# psoc6_04 register map
Vendor: Cypress Semiconductor; Series: PSoC6_04; File version: 1.0
CPU: CM4 r0p1, little endian, MPU, FPU, VTOR, 3 interrupt priority bits
Registers are 32-bit, read-write, reset 0x0 unless marked. A register's access mark holds for its fields unless they carry their own. Offsets are from the block's base; [hi:lo] are bit positions; lines under a group give offsets from that group; {n}, {i} and the like mark numbered series; <NAME> marks a mode.

## PASS — PASS top-level MMIO (AREF, LPOSC, FIFO, INTR, Trigger)
Base 0x409F0000
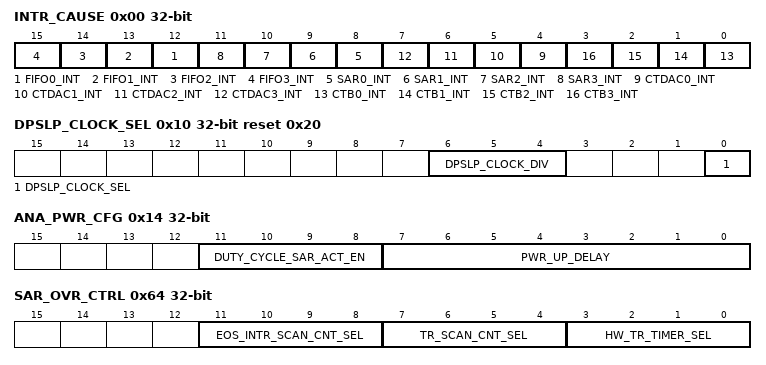
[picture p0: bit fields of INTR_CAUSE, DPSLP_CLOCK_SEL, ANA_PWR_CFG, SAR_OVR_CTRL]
0x00 INTR_CAUSE ro — Interrupt cause register
  [n+12] FIFO{n}_INT (n=0..3) — FIFO{n} interrupt pending
  [n+8] SAR{n}_INT (n=0..3) — SAR{n} interrupt pending
  [n+4] CTDAC{n}_INT (n=0..3) — CTDAC{n} interrupt pending
  [n] CTB{n}_INT (n=0..3) — CTB{n} interrupt pending
0x10 DPSLP_CLOCK_SEL reset 0x20 — Deepsleep clock select
  [6:4] DPSLP_CLOCK_DIV — CLK_DPSLP divider
    0=NO_DIV (Transparent mode, feed through selected clock source w/o dividing.); 1=DIV_BY_2 (Divide selected clock source by 2); 2=DIV_BY_4 (Divide selected clock source by 4); 3=DIV_BY_8 (Divide selected clock source by 8); 4=DIV_BY_16 (Divide selected clock source by 16); 5=RSVD_0 (N/A); 6=RSVD_1 (N/A); 7=RSVD_2 (N/A)
  [0] DPSLP_CLOCK_SEL — Select source for PASS DPSLP Clock
    0=CLK_LPOSC (CLK_DPSLP is set to CLK_LPOSC); 1=CLK_MF (CLK_DPSLP is set to CLK_MF)
0x14 ANA_PWR_CFG — Analog power configuration
  [11:8] DUTY_CYCLE_SAR_ACT_EN — Enable for powering down (duty cycling) a SAR in chip active mode. This is a risk mitigation bit for power reduction in chip active mode. In order for this field affect SAR operation, the SAR must be configured for deepsleep clocking (SAR_CLOCK_SEL.CLOCK_SEL set to 1), and the SAR must be set for Timer-based hardware triggering (either by following the guidlines in SAR_OVR_CTRL.HW_TR_TIMER_SEL or SAR_SIMULT_CTRL.SIMULT_HW_TIMER_SEL). If this bit is set for a given SAR, the Timer is the only valid trigger source. Non-timer based Hardware (DSI) triggers cannot be used nor can Firmware based triggers (FW,Continuous,Injection). Furthermore, trigger collision functionality will be limited to interrupt generation only. -0: Legacy (SAR not duty cycled in chip active mode -1: SAR duty cycled in chip active mode <0>: Active Mode Duty Cycle enable for SAR0 <1>: Active Mode Duty Cycle enable for SAR1 <2>: Active Mode Duty Cycle enable for SAR2 <3>: Active Mode Duty Cycle enable for SAR3 This field is only applicable when SAR_CLOCK_SEL.CLOCK_SEL =1. This field can also affect LPOSC functionality in Active Mode (see LPOSC CONFIG.DEEPSLEEP_MODE field for details)
  [7:0] PWR_UP_DELAY — Power up time for analog blocks. Fastest power up time is achieved with a setting of 0. Additional time can be added to allow for analog settling. The power up time is in clk_dpslp cycles. This field is only applicable when SAR_CLOCK_SEL.CLOCK_SEL =1.
{0x20+4i} CTBM_CLOCK_SEL[{i}] (i=0..1) — Clock select for CTBm
  [0] PUMP_CLOCK_SEL — Select source for CTBm Pump Clock.
    0=LEGACY (CTBm pump clock set by AREF.CTRL.CLOCK_PUMP_PERI_SEL (Legacy). When configured for legacy operation, the CTBm deeplseep functionality is determined solely by the CTRL.DEEPSLEEP_ON bit.); 1=CLK_DPSLP (CTBm pump clock sourced from CLK_DPSLP When configured for CLK_DPSLP operation, the CTBm deepsleep functionality is determined by the CTRL.DEEPSLEEP_ON bit AND SAR(s) operation (i.e. CTBm is duty cycled with the SAR(s)). In this mode, the CTBm should only be used as a buffer/gain stage for the SAR(s).)
{0x30+4i} SAR_DPSLP_CTRL[{i}] (i=0..1) — Deepsleep control for SARv3
  [31] ENABLED — enable for SAR deepsleep operation. SAR_CLOCK_SEL.CLOCK_SEL must be set to 1 for this field to affect SAR operation. - 0: SAR deeepsleep operation disabled - 1: SAR deepsleep operation enabled.
{0x40+4i} SAR_CLOCK_SEL[{i}] (i=0..1) — Clock select for SARv3
  [30] CLOCK_SEL — SAR clock select
    0=LEGACY (- 0: legacy: SAR clock source is CLK_PERI (SAR is only operational in chip ACTIVE mode)); 1=CLK_DPSLP (- 1: SAR clock source is CLK_DPSLP (SAR can be operational in both chip ACTIVE and DEEPSLEEP modes))
{0x50+4i} SAR_TR_SCAN_CNT_STATUS[{i}] (i=0..1) ro — SAR trigger scan control status
  [7:0] SCAN_CNT_STATUS — A read from this register returns the current sample count (possible values are 1 through SCAN_TR_SCAN_CNT.SCAN_CNT+1). This field cannot be read if SAR_CLOCK_SEL.CLOCK_SEL =1.
0x60 SAR_TR_SCAN_CNT — SAR trigger scan control
  [7:0] SCAN_CNT — SAR trigger sample counter. This field determines the number of samples a SAR will take when triggered. The number of samples is SCAN_COUNT+1. This feature can be enabled for individual SARs by setting the appropriate bit of SAR_TR_CTRL.TR_SCAN_CNT_SEL. This feature can be enabled for simultaneously sampled SARs by setting SAR_SIMULT_TR_CTRL.SIMULT_TR_SCAN_CNT_SEL. If SAR.SAMPLE_CTRL.AVG_MODE is set to INTERLEAVED, the SCAN_CNT must be set an integer multiple of (1<<AVG_CNTR+1).
0x64 SAR_OVR_CTRL — SAR HW trigger override
  [11:8] EOS_INTR_SCAN_CNT_SEL — SAR EOS interrupt source select (one bit per SAR). This feature is not available for FW or Continuous triggering. -0: Legacy (SAR EOS is the source of the SAR EOS interrupt) -1: Enabled, SAR EOS interrupt only occurs for the EOS when sample=SAR_TR_SCAN_CNT.SCAN_CNT. <0>: EOS interrupt sample count select for SAR0 <1>: EOS interrupt sample count select for SAR1 <2>: EOS interrupt sample count select for SAR2 <3>: EOS interrupt sample count select for SAR3
  [7:4] TR_SCAN_CNT_SEL — SAR trigger sample select (one bit per SAR). -0: Disabled -1: Enabled, SAR takes SAR_TR_SCAN_CNT per trigger (valid for both Firmware and Edge Senstive Hardware triggering, but ignored for Level Sensitive Hardware triggering and CONTINUOUS triggering). This feature cannot be enabled if the SAR is configured for Non-Tailgating Injection (SAR.INJ_CHAN_CONFIG.INJ_TAILGATING=0 while SAR.INJ_CHAN_CONFIG.INJ_START_EN=1) <0>: trigger sample select for SAR0 <1>: trigger sample select for SAR1 <2>: trigger sample select for SAR2 <3>: trigger sample select for SAR3
  [3:0] HW_TR_TIMER_SEL — SAR hardware trigger source select (one bit per SAR). SAR must be configured for hardware triggering (SAR.SAMPLE_CTRL.DSI_TRIGGER_EN must be set to 1). -0: Legacy (tr_sar_in_<N>) -1: Timer trigger <0>: HW Trigger source for SAR0 <1>: HW Trigger source for SAR1 <2>: HW Trigger source for SAR2 <3>: HW Trigger source for SAR3
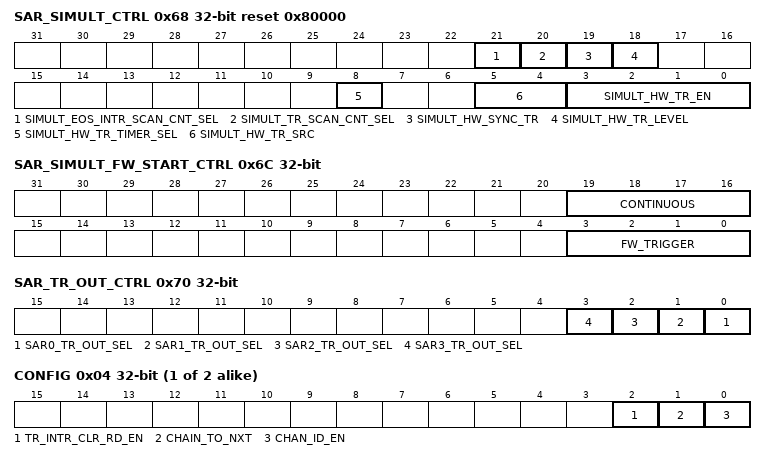
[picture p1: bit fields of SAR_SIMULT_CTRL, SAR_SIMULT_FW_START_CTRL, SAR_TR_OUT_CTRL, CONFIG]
0x68 SAR_SIMULT_CTRL reset 0x80000 — SAR simultaneous trigger control
  [21] SIMULT_EOS_INTR_SCAN_CNT_SEL — Simultaneous SAR EOS interrupt source select. This feature is not available for FW or Continuous triggering. -0: Legacy (SAR EOS is the source of the SAR EOS interrupt) -1: Enabled, SAR EOS interrupt only occurs for the EOS when sample=SAR_TR_SCAN_CNT.SCAN_CNT.
  [20] SIMULT_TR_SCAN_CNT_SEL — Simultaneous trigger sample select -0: Disabled -1: Enabled, SAR takes SAR_TR_SCAN_CNT per trigger (valid for both Firmware and Edge Senstive Hardware triggering, but ignored for Level Sensitive Hardware triggering and CONTINUOUS triggering) This feature cannot be enabled if either SAR is configured for Non-Tailgating Injection (SAR.INJ_CHAN_CONFIG.INJ_TAILGATING=0 while SAR.INJ_CHAN_CONFIG.INJ_START_EN=1)
  [19] SIMULT_HW_SYNC_TR — - 0: bypass clock domain synchronization of the Simult trigger signal. - 1: synchronize the Simult trigger signal to the SAR clock domain, if needed an edge detect is done in the peripheral clock domain.
  [18] SIMULT_HW_TR_LEVEL — - 0: trigger signal is a pulse input, a positive edge detected on the trigger signal triggers a new scan. - 1: trigger signal is a level input, as long as the trigger signal remains high the SAR will do continuous scans. This field cannot be set when SAR_CLOCK_SEL.CLOCK_SEL =1.
  [8] SIMULT_HW_TR_TIMER_SEL — SAR hardware trigger source select -0: SIMULT_HW_TR_SRC -1: Timer trigger
  [5:4] SIMULT_HW_TR_SRC — Source for Simult Hardware trigger
    {v}=SAR_TR_IN_{v} (SAR {v} HW Trigger Input) (v=0..3)
  [3:0] SIMULT_HW_TR_EN — SAR simultaneous hardware triggering enable (one bit per SAR) -0: disabled -1: SAR trigger override enabled (SAR trigger set by SAR_OVR_CTRL register) <0>: Simultaneuous sampling enable for SAR0 <1>: Simultaneuous sampling enable for SAR1 <2>: Simultaneuous sampling enable for SAR2 <3>: Simultaneuous sampling enable for SAR3 Simultaneous sampling requires at least two bits in this field to be set. If less than two bits are set, this register will not affect SAR operation.
0x6C SAR_SIMULT_FW_START_CTRL — SAR simultaneous start control
  [19:16] CONTINUOUS — This field is used to configure two or more SARs for continuous operation. -0: Continuous mode disabled -1: Continuously scan enabled channels, ignore triggers. <0>: Continuous Mode for SAR0 <1>: Continuous Mode for SAR1 <2>: Continuous Mode for SAR2 <3>: Continuous Mode for SAR3 If less than two bits are set, this field has no effect. This field cannot be set when SAR_CLOCK_SEL.CLOCK_SEL =1.
  [3:0] FW_TRIGGER — This field is used to simultaneously FW trigger two or more SARs. <0>: Firmware trigger for SAR0 <1>: Firmware trigger for SAR1 <2>: Firmware trigger for SAR2 <3>: Firmware trigger for SAR3 If less than two bits are set, this field has no effect. When firmware writes to this field it will trigger the next scan of enabled channels, hardware clears this bit when the scan started with this trigger is completed. If scanning continuously the trigger is ignored and hardware clears this bit after the next scan is done. This bit is also cleared when the SAR is disabled. This field cannot be set when SAR_CLOCK_SEL.CLOCK_SEL =1.
0x70 SAR_TR_OUT_CTRL — SAR trigger out control
  [all] fields
    0=LEGACY (sar output trigger is set by SAR.SAMPLE_CTRL.EOS_DSI_OUT_EN condition); 1=BUFFER_TRIGGER_LEVEL (sar output trigger is set by FIFO.CTRL.FIFO_LEVEL condition)
  [n] SAR{n}_TR_OUT_SEL (n=0..3) — SAR{n} Trigger Out Source Select
0x100 TIMER group — Programmable Analog Subsystem
  0x00 CTRL — Timer trigger control register
    [31] ENABLED — 0=disabled, 1=enabled Upon enable, the timer will immediately generate a trigger pulse (lasting for one clock cycle of the selected CONFIF.CLOCK_SEL) and will generate subsequent trigger pulses (again lasting one clock cycle) whenever the timer reaches terminal count. If PERIOD.PER_VAL is set to 0, the timer trigger output will remain high as long as the timer is enabled.
  0x04 CONFIG — Timer trigger configuration register
    [1:0] CLOCK_SEL — Select Clock source of the Timer
      0=CLK_PERI (Timer clocked from CLK_PERI); 1=CLK_DPSLP (Timer clocked from CLK_DPSLP); 2=CLK_LF (Timer clocked from CLK_LF); 3=TBD (N/A)
  0x08 PERIOD — Timer trigger period register
    [15:0] PER_VAL — Actual timer period is PER_VAL+1 (1 to 65536). Only non-zero PER_VAL are supported. (i.e. PER_VAL=0 is considered invalid).
0x200 LPOSC group — LPOSC configuration
  0x00 CTRL reset 0x80000000 — Low Power Oscillator control
    [31] ENABLED — Master enable for LPOSC oscillator. This bit must be high at all times for all functions to work properly. Hardware will automatically disable the LPOSC during DEEPSLEEP (unless DEEPSLEEP_MODE is set)
  0x04 CONFIG — Low Power Oscillator configuration register
    [0] DEEPSLEEP_MODE — LPOSC functionality while in DEEPSLEEP. If the ANA_PWR_CFG.DUTY_CYCLE_SAR_ACT_EN bit of a Deepsleep configured SAR is set, the DEEPSLEEP_MODE field for the LPOSC also applies to chip active mode (i.e. the LPOSC will get duty cycled in chip active mode if DEEPSLEEP_MODE=0 and DUTY_CYLE_SAR_ACT_EN=1 for all Deepsleep enabled SAR(s))
      0=DUTYCYCLED (LPOSC enabled by TIMER trigger); 1=ALWAYS_ON (LPOSC always on in deepsleep)
  0x08 ADFT — Retention, Hidden
    [1:0] ADFT_SEL — ADFT selection for LPOSC. 0: DFT disabled 1: Measure Vdo; expect ~0.8V 2: Measure Ibias_ptat; expect ~250nA 3: Measure Ibias_ctat; expect ~550nA
{0x300+0x100*i} FIFO[{i}] (i=0..1) group — FIFO configuration
  0x00 CTRL — FIFO control register
    [31] ENABLED — Enable for SAR FIFO functionality. If CONFIG.CHAIN_TO_NXT is set, the ENABLED bit of the NEXT FIFO is set when FIFO[0] is enabled. - 0: FIFO disabled - 1: FIFO enabled
  0x04 CONFIG — FIFO configuration register
    [2] TR_INTR_CLR_RD_EN — Enable for FIFO read clearing the FIFO level trigger and level interrupt. - 0: Disabled, FIFO level trigger and level interrupt generation follows LEVEL.LEVEL. - 1: Enabled, after initial FIFO level trigger and level interrupt generation, subsequent FIFO level triggers and level interrupts are blocked until at least FIFO.LEVEL+1 reads have occurred. If CHAIN_TO_NXT is enabled, only FIFO[0].CONFIG. TR_CLR_RD_EN should be configured.
    [1] CHAIN_TO_NXT — Chain FIFO to next FIFO (i.e. chain FIFO0 and FIFO1). - 0: FIFO not chained . FIFO operates independently (FIFO depth of 64) and only operates on result data from its associated SAR. - 1: FIFO chained to next FIFO. FIFO is part of a chain of FIFOs (effectively extending the FIFO depth beyond 64) and only operates on result data from SAR0.
    [0] CHAN_ID_EN — channel number (ID) enable bit -0: CHAN_ID field in RD_DATA is disabled. A read from RD_DATA will result in (4'b0,16'b RESULT) -1: CHAN_ID field in RD_DATA is enabled. A read from RD_DATA will result in (4'b CHAN_ID, 16'b RESULT) If CHAIN_EN is enabled, only FIFO[0].config.chan_id_en should be configured and the other FIFOs in the chain will inherit the FIFO[0] config.
  0x08 CLEAR — FIFO clear register
    [0] CLEAR — When firmware writes a 1 here it will trigger and clearing of the FIFO status registers (excluding interrupts), hardware clears this bit.
  0x0C LEVEL — FIFO level register
    [7:0] LEVEL — FIFO level set. A trigger (and optional interrupt) event occurs when USED.USED = LEVEL+1. (Trigger generation is also affect by CONFIG.TR_CLR_RD_EN). If CHAIN_TO_NXT is disabled, the Max LEVEL is limited to 63. If CHAIN_TO_NXT is enabled, only FIFO[0].config.level should be configured and the Max LEVEL is set by the number of FIFOs in the chain.
  0x10 USED ro — FIFO used register
    [7:0] USED — Number of used/occupied entries in the FIFO. If CONFIG.CHAIN_EN is disabled, the field value is in the range [0, 64]. When '0', the FIFO is empty. When '64', the FIFO is full. If CONFIG.CHAIN_EN is enabled, only FIFO[0].USED.USED should be read to detemine the used status.
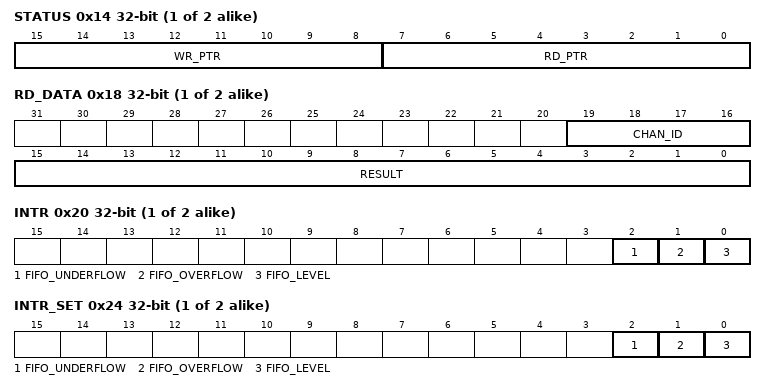
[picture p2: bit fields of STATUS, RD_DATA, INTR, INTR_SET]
  0x14 STATUS ro — FIFO status register
    [15:8] WR_PTR — FIFO write pointer: FIFO location at which a new data is written by the hardware. Note: This functionality is intended for debugging purposes. If CONFIG.CHAIN_TO_NXT is enabled, only FIFO[0].STATUS.WR_PTR should be read to detemine the write pointer location of the chained FIFO.
    [7:0] RD_PTR — FIFO read pointer: FIFO location from which a data is read. Note: This functionality is intended for debugging purposes. If CONFIG.CHAIN_TO_NXT is enabled, only FIFO[0].STATUS.RD_PTR should be read to detemine the read pointer location of the chained FIFO.
  0x18 RD_DATA ro — FIFO read data register
    [19:16] CHAN_ID — Channel number for a given SAR result. Requires CTRL.CHAN_ID_EN to be set. If CONFIG.CHAIN_TO_NXT is enabled, only FIFO[0].RD_DATA.CHAN_ID should be read.
    [15:0] RESULT — SAR result. Results from all enabled channels are stored in the buffer. If CONFIG.CHAIN_TO_NXT is enabled, only FIFO[0].RD_DATA.RESULT should be read.
  0x20 INTR — Interrupt register
    [2] FIFO_UNDERFLOW — HW sets this field to '1', when reading from an empty FIFO. HW tracks underflow after FIFO is being written to and FIFO_CTL.ENABLE==1. If CONFIG.CHAIN_TO_NXT is enabled, only FIFO[0].INTR.FIFO_UNDERFLOW is updated by hardware. Write with '1' to clear bit.
    [1] FIFO_OVERFLOW — HW sets this field to '1', when writing to a full FIFO (FIFO_STATUS.USED is '64'). If CONFIG.CHAIN_TO_NXT is enabled, only FIFO[0].INTR.FIFO_OVERFLOW is updated by hardware. Write with '1' to clear bit.
    [0] FIFO_LEVEL — HW sets this field to '1', when STATUS.USED >= CTRL.LEVEL+1 If CONFIG.CHAIN_TO_NXT is enabled, only FIFO[0].INTR.FIFO_LEVEL is updated by hardware. Write with '1' to clear bit.
  0x24 INTR_SET — Interrupt set register
    [2] FIFO_UNDERFLOW — Write this field with '1' to set corresponding INTR field (a write of '0' has no effect).
    [1] FIFO_OVERFLOW — Write this field with '1' to set corresponding INTR field (a write of '0' has no effect).
    [0] FIFO_LEVEL — Write this field with '1' to set corresponding INTR field (a write of '0' has no effect).
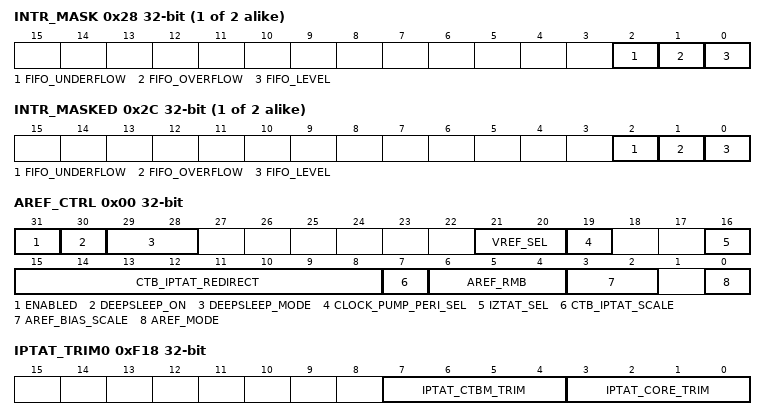
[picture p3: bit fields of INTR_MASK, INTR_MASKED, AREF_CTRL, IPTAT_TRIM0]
  0x28 INTR_MASK — Interrupt mask register
    [2] FIFO_UNDERFLOW — Mask for corresponding field in INTR register. If CONFIG.CHAIN_TO_NXT is enabled, only FIFO[0].INTR_MASK.FIFO_UNDERFLOW should be set.
    [1] FIFO_OVERFLOW — Mask for corresponding field in INTR register. If CONFIG.CHAIN_TO_NXT is enabled, only FIFO[0].INTR_MASK.FIFO_OVERFLOW should be set.
    [0] FIFO_LEVEL — Mask for corresponding field in INTR register. If CONFIG.CHAIN_TO_NXT is enabled, only FIFO[0].INTR_MASK.FIFO_LEVEL should be set.
  0x2C INTR_MASKED ro — Interrupt masked register
    [2] FIFO_UNDERFLOW — Logical AND of corresponding INTR and INTR_MASK fields.
    [1] FIFO_OVERFLOW — Logical AND of corresponding INTR and INTR_MASK fields.
    [0] FIFO_LEVEL — Logical AND of corresponding INTR and INTR_MASK fields.
0xE00 AREFV2 group — AREF configuration
  0x00 AREF_CTRL — global AREF control
    [31] ENABLED — Disable AREF
    [30] DEEPSLEEP_ON — - 0: AREF IP disabled/off during DeepSleep power mode - 1: AREF IP remains enabled during DeepSleep power mode (if ENABLED=1)
    [29:28] DEEPSLEEP_MODE — AREF DeepSleep Operation Modes (only applies if DEEPSLEEP_ON = 1)
      0=OFF (All blocks 'OFF' in DeepSleep); 1=IPTAT (IPTAT bias generator 'ON' in DeepSleep (used for fast AREF wakeup only: IPTAT outputs not available)); 2=IPTAT_IZTAT (IPTAT bias generator and outputs 'ON' in DeepSleep (used for biasing the CTBm with a PTAT current only in deep sleep) *Note that this mode also requires that the CTB_IPTAT_REDIRECT be set if the CTBm opamp is to operate in DeepSleep); 3=IPTAT_IZTAT_VREF (IPTAT, VREF, and IZTAT generators 'ON' in DeepSleep. This mode provides identical AREF functionality in DeepSleep as in the Active mode.)
    [21:20] VREF_SEL — bandgap voltage select control
      0=SRSS (Use 0.8V Vref from SRSS); 1=LOCAL (Use locally generated Vref); 2=EXTERNAL (Use externally supplied Vref (aref_ext_vref))
    [19] CLOCK_PUMP_PERI_SEL — CTBm charge pump clock source select. This field has nothing to do with the AREF. 0: Use the dedicated pump clock from SRSS (default) 1: Use one of the CLK_PERI dividers
    [16] IZTAT_SEL — iztat current select control
      0=SRSS (Use 250nA IZTAT from SRSS); 1=LOCAL (Use locally generated 250nA)
    [15:8] CTB_IPTAT_REDIRECT — Re-direct the CTB IPTAT output current. This can be used to reduce amplifier bias glitches during power mode transitions (for PSoC4A/B DSAB backwards compatibility). 0: Opamp<n>.IPTAT = AREF.IPTAT and Opamp<n>.IZTAT= AREF.IZTAT 1: Opamp<n>.IPTAT = HiZ and Opamp<n>.IZTAT= AREF.IPTAT *Note that in Deep Sleep, the AREF IZTAT and/or IPTAT currents can be disabled and therefore the corresponding Opamp<n>.IZTAT/IPTAT will be HiZ.
    [7] CTB_IPTAT_SCALE — CTB IPTAT current scaler. This bit must be set in order to operate the CTB amplifiers in the lowest power mode. This bit is chip-wide (controls all CTB amplifiers). 0: 1uA 1: 100nA
    [6:4] AREF_RMB — AREF control signals (RMB). Bit 0: Manual VBG startup circuit enable 0: normal VBG startup circuit operation 1: VBG startup circuit is forced 'always on' Bit 1: Manual disable of IPTAT2 DAC 0: normal IPTAT2 DAC operation 1: PTAT2 DAC is disabled while VBG startup is active Bit 2: Manual enable of VBG offset correction DAC 0: normal VBG offset correction DAC operation 1: VBG offset correction DAC is enabled while VBG startup is active
    [3:2] AREF_BIAS_SCALE — BIAS Current Control for all AREF Amplifiers. (These are risk mitigation bits that should not be touched by the customer: the impact on IDDA/noise/startup still needs to be characterized) 0: 125nA (reduced bias: reduction in total AREF IDDA, higher noise and longer startup times) 1: 250nA ('default' setting to meet bandgap performance (noise/startup) and IDDA specifications) 2: 375nA (increased bias: increase in total AREF IDDA, lower noise and shorter startup times) 3: 500nA (further increased bias: increase in total AREF IDDA, lower noise and shorter startup times)
    [0] AREF_MODE — Control bit to trade off AREF settling and noise performance
      0=NORMAL (Nominal noise normal startup mode (meets normal mode settling and noise specifications)); 1=FAST_START (High noise fast startup mode (meets fast mode settling and noise specifications))
0xF00 VREF_TRIM0 — VREF Trim bits
  [7:0] VREF_ABS_TRIM
0xF04 VREF_TRIM1 — VREF Trim bits
  [7:0] VREF_TEMPCO_TRIM
0xF08 VREF_TRIM2 — VREF Trim bits
  [7:0] VREF_CURV_TRIM
0xF0C VREF_TRIM3 — VREF Trim bits
  [3:0] VREF_ATTEN_TRIM — Obsolete
0xF10 IZTAT_TRIM0 — VREF Trim bits
  [7:0] IZTAT_ABS_TRIM
0xF14 IZTAT_TRIM1 — IZTAT Trim bits
  [7:0] IZTAT_TC_TRIM — IZTAT temperature correction trim (RMB) 0x00 : No IZTAT temperature correction 0xFF : Maximum IZTAT temperature correction As this is a Risk Mitigation Register, it should be loaded with 0x08.
0xF18 IPTAT_TRIM0 — IPTAT Trim bits
  [7:4] IPTAT_CTBM_TRIM — CTMB PTAT Current Trim 0x0 : Minimum CTMB IPTAT Current (~875nA) 0xF : Maximum CTMB IPTAT Current (~1.1uA)
  [3:0] IPTAT_CORE_TRIM — IPTAT trim 0x0 : Minimum IPTAT current (~150nA at room) 0xF : Maximum IPTAT current (~350nA at room)
0xF1C ICTAT_TRIM0 — ICTAT Trim bits
  [3:0] ICTAT_TRIM — ICTAT trim 0x00 : Minimum ICTAT current (~150nA at room) 0x0F : Maximum ICTAT current (~350nA at room)

## Notices in the file
(c) (2016-2021), Cypress Semiconductor Corporation (an Infineon company)
or an affiliate of Cypress Semiconductor Corporation.
SPDX-License-Identifier: Apache-2.0
Licensed under the Apache License, Version 2.0 (the "License");
you may not use this file except in compliance with the License.
You may obtain a copy of the License at
http://www.apache.org/licenses/LICENSE-2.0
Unless required by applicable law or agreed to in writing, software
distributed under the License is distributed on an "AS IS" BASIS,
WITHOUT WARRANTIES OR CONDITIONS OF ANY KIND, either express or implied.
See the License for the specific language governing permissions and
limitations under the License.
